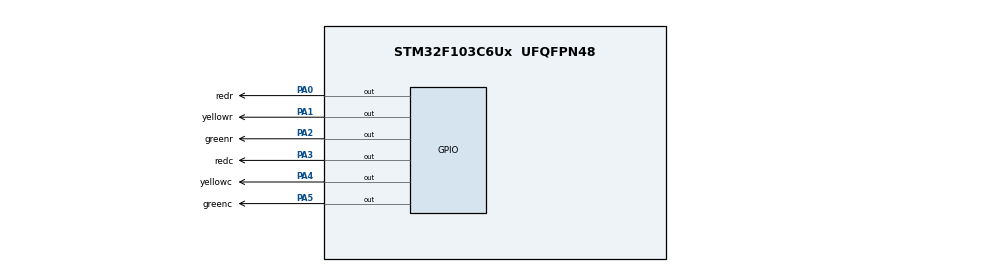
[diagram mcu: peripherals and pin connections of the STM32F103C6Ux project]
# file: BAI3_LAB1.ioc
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Mcu.Family=STM32F1
Mcu.Name=STM32F103C6Ux
Mcu.Package=UFQFPN48
NVIC.PriorityGroup=NVIC_PRIORITYGROUP_4
PA0-WKUP.GPIO_Label=redr
PA0-WKUP.Signal=GPIO_Output
PA1.GPIO_Label=yellowr
PA1.Signal=GPIO_Output
PA2.GPIO_Label=greenr
PA2.Signal=GPIO_Output
PA3.GPIO_Label=redc
PA3.Signal=GPIO_Output
PA4.GPIO_Label=yellowc
PA4.Signal=GPIO_Output
PA5.GPIO_Label=greenc
PA5.Signal=GPIO_Output
ProjectManager.HeapSize=0x200
ProjectManager.StackSize=0x400
ProjectManager.TargetToolchain=STM32CubeIDE
RCC.APB1Freq_Value=8000000
RCC.APB2Freq_Value=8000000
VP_SYS_VS_ND.Mode=No_Debug
board=custom

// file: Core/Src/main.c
/* USER CODE BEGIN Header */
/**
  ******************************************************************************
  * @file           : main.c
  * @brief          : Main program body
  ******************************************************************************
  * @attention
  *
  * <h2><center>&copy; Copyright (c) 2022 STMicroelectronics.
  * All rights reserved.</center></h2>
  *
  * This software component is licensed by ST under BSD 3-Clause license,
  * the "License"; You may not use this file except in compliance with the
  * License. You may obtain a copy of the License at:
  *                        opensource.org/licenses/BSD-3-Clause
  *
  ******************************************************************************
  */
/* USER CODE END Header */
#include "main.h"

void SystemClock_Config(void);
static void MX_GPIO_Init(void);

int main(void)
{

  /* MCU Configuration--------------------------------------------------------*/

  /* Reset of all peripherals, Initializes the Flash interface and the Systick. */
  HAL_Init();

  /* Configure the system clock */
  SystemClock_Config();

  /* Initialize all configured peripherals */
  MX_GPIO_Init();

  /* Infinite loop */
  /* USER CODE BEGIN WHILE */
  int count = 10;
  while (1)
  {
    /* USER CODE END WHILE */
    count--;
    if (count >= 7 && count <= 9) {
    	// led red_row, green_column turn on
    	// led yellow_row, yellow_column, red_column, green_row turn off
    	// when time is between 9->7
      	HAL_GPIO_WritePin(GPIOA, redr_Pin|greenc_Pin, RESET);
      	HAL_GPIO_WritePin(GPIOA, yellowr_Pin|yellowc_Pin|redc_Pin|greenr_Pin, SET);
    }
    else if(count <= 6 && count >= 5){
    	// turn off led green_column and turn on yellow_column
    	// when time is between 6->5
      	HAL_GPIO_WritePin(yellowc_GPIO_Port, yellowc_Pin, RESET);
      	HAL_GPIO_WritePin(greenc_GPIO_Port, greenc_Pin, SET);
    }
    else if(count <= 4 && count >= 2){
    	// turn off led: yellow_column, red_row
    	// turn on led: red_column, green_row
    	// when time is between 2->4
    	HAL_GPIO_WritePin(GPIOA, redr_Pin|yellowc_Pin, SET);
      	HAL_GPIO_WritePin(GPIOA, redc_Pin|greenr_Pin, RESET);
    }
    else if(count <= 1 && count >= 0){
    	// turn off led: green_row
    	// turn on led:	yellow_row
    	// when time is between 0->1
    	HAL_GPIO_WritePin(greenr_GPIO_Port, greenr_Pin, SET);
    	HAL_GPIO_WritePin(yellowr_GPIO_Port, yellowr_Pin, RESET);
      	if(count == 0)	count = 10;
    }
    HAL_Delay(1000);
  }
}

void SystemClock_Config(void)
{
  RCC_OscInitTypeDef RCC_OscInitStruct = {0};
  RCC_ClkInitTypeDef RCC_ClkInitStruct = {0};

  /** Initializes the RCC Oscillators according to the specified parameters
  * in the RCC_OscInitTypeDef structure.
  */
  RCC_OscInitStruct.OscillatorType = RCC_OSCILLATORTYPE_HSI;
  RCC_OscInitStruct.HSIState = RCC_HSI_ON;
  RCC_OscInitStruct.HSICalibrationValue = RCC_HSICALIBRATION_DEFAULT;
  RCC_OscInitStruct.PLL.PLLState = RCC_PLL_NONE;
  if (HAL_RCC_OscConfig(&RCC_OscInitStruct) != HAL_OK)
  {
    Error_Handler();
  }
  /** Initializes the CPU, AHB and APB buses clocks
  */
  RCC_ClkInitStruct.ClockType = RCC_CLOCKTYPE_HCLK|RCC_CLOCKTYPE_SYSCLK
                              |RCC_CLOCKTYPE_PCLK1|RCC_CLOCKTYPE_PCLK2;
  RCC_ClkInitStruct.SYSCLKSource = RCC_SYSCLKSOURCE_HSI;
  RCC_ClkInitStruct.AHBCLKDivider = RCC_SYSCLK_DIV1;
  RCC_ClkInitStruct.APB1CLKDivider = RCC_HCLK_DIV1;
  RCC_ClkInitStruct.APB2CLKDivider = RCC_HCLK_DIV1;

  if (HAL_RCC_ClockConfig(&RCC_ClkInitStruct, FLASH_LATENCY_0) != HAL_OK)
  {
    Error_Handler();
  }
}

static void MX_GPIO_Init(void)
{
  GPIO_InitTypeDef GPIO_InitStruct = {0};

  /* GPIO Ports Clock Enable */
  __HAL_RCC_GPIOA_CLK_ENABLE();

  /*Configure GPIO pin Output Level */
  HAL_GPIO_WritePin(GPIOA, redr_Pin|yellowr_Pin|greenr_Pin|redc_Pin
                          |yellowc_Pin|greenc_Pin, GPIO_PIN_RESET);

  /*Configure GPIO pins : redr_Pin yellowr_Pin greenr_Pin redc_Pin
                           yellowc_Pin greenc_Pin */
  GPIO_InitStruct.Pin = redr_Pin|yellowr_Pin|greenr_Pin|redc_Pin
                          |yellowc_Pin|greenc_Pin;
  GPIO_InitStruct.Mode = GPIO_MODE_OUTPUT_PP;
  GPIO_InitStruct.Pull = GPIO_NOPULL;
  GPIO_InitStruct.Speed = GPIO_SPEED_FREQ_LOW;
  HAL_GPIO_Init(GPIOA, &GPIO_InitStruct);

}

void Error_Handler(void)
{
  __disable_irq();
  while (1)
  {
  }
}

/************************ (C) COPYRIGHT STMicroelectronics *****END OF FILE****/
